# BL808 register map
Vendor: Bouffalo Lab; File version: 0.1
Registers are 32-bit, read-write, reset 0x0 unless marked. A register's access mark holds for its fields unless they carry their own. Offsets are from the block's base; [hi:lo] are bit positions; {n}, {i} and the like mark numbered series.

## TZC_NSEC — Trust zone isolation 2
Base 0x20006000
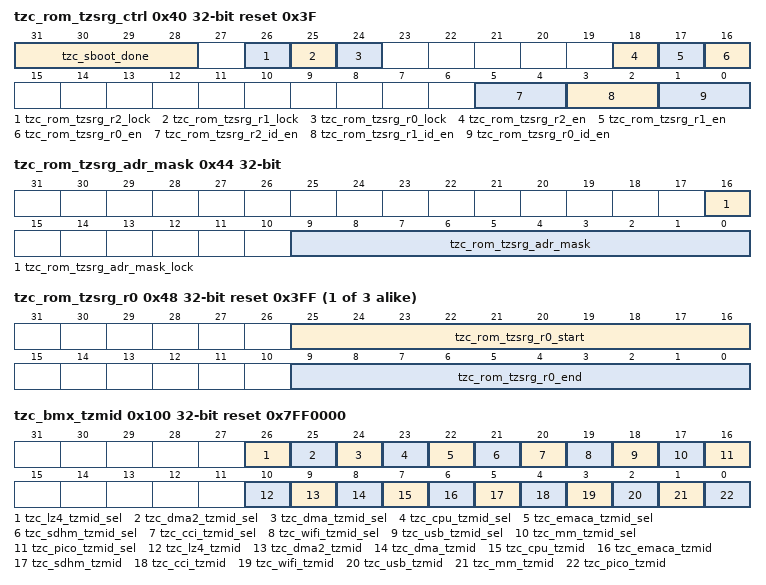
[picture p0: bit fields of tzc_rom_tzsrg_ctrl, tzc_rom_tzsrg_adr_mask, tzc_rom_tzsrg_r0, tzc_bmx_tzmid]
0x40 tzc_rom_tzsrg_ctrl reset 0x3F
  [31:28] tzc_sboot_done ro, [26] tzc_rom_tzsrg_r2_lock ro, [25] tzc_rom_tzsrg_r1_lock ro, [24] tzc_rom_tzsrg_r0_lock ro, [18] tzc_rom_tzsrg_r2_en ro, [17] tzc_rom_tzsrg_r1_en ro, [16] tzc_rom_tzsrg_r0_en ro, [5:4] tzc_rom_tzsrg_r2_id_en ro, [3:2] tzc_rom_tzsrg_r1_id_en ro, [1:0] tzc_rom_tzsrg_r0_id_en ro
0x44 tzc_rom_tzsrg_adr_mask
  [16] tzc_rom_tzsrg_adr_mask_lock ro, [9:0] tzc_rom_tzsrg_adr_mask ro
{0x48+4i} tzc_rom_tzsrg_r{i} reset 0x3FF (i=0..2)
  [25:16] tzc_rom_tzsrg_r{i}_start ro, [9:0] tzc_rom_tzsrg_r{i}_end ro
0x54 tzc_rom_tzsrg_r3
0x100 tzc_bmx_tzmid reset 0x7FF0000
  [26] tzc_lz4_tzmid_sel ro, [25] tzc_dma2_tzmid_sel ro, [24] tzc_dma_tzmid_sel ro, [23] tzc_cpu_tzmid_sel ro, [22] tzc_emaca_tzmid_sel ro, [21] tzc_sdhm_tzmid_sel ro, [20] tzc_cci_tzmid_sel ro, [19] tzc_wifi_tzmid_sel ro, [18] tzc_usb_tzmid_sel ro, [17] tzc_mm_tzmid_sel ro, [16] tzc_pico_tzmid_sel ro, [10] tzc_lz4_tzmid ro, [9] tzc_dma2_tzmid ro, [8] tzc_dma_tzmid ro, [7] tzc_cpu_tzmid ro, [6] tzc_emaca_tzmid ro, [5] tzc_sdhm_tzmid ro, [4] tzc_cci_tzmid ro, [3] tzc_wifi_tzmid ro, [2] tzc_usb_tzmid ro, [1] tzc_mm_tzmid ro, [0] tzc_pico_tzmid ro
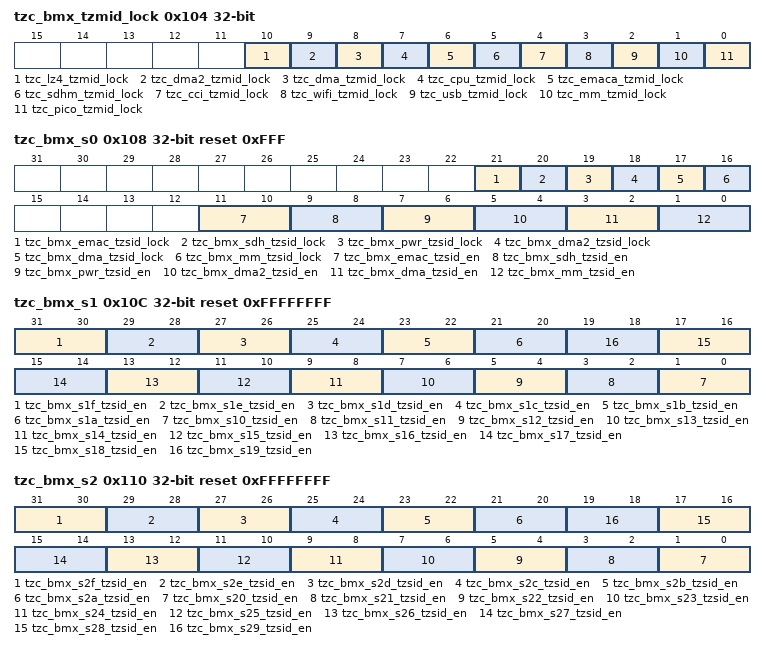
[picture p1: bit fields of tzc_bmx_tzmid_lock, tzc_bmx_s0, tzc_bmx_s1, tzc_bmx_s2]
0x104 tzc_bmx_tzmid_lock
  [10] tzc_lz4_tzmid_lock ro, [9] tzc_dma2_tzmid_lock ro, [8] tzc_dma_tzmid_lock ro, [7] tzc_cpu_tzmid_lock ro, [6] tzc_emaca_tzmid_lock ro, [5] tzc_sdhm_tzmid_lock ro, [4] tzc_cci_tzmid_lock ro, [3] tzc_wifi_tzmid_lock ro, [2] tzc_usb_tzmid_lock ro, [1] tzc_mm_tzmid_lock ro, [0] tzc_pico_tzmid_lock ro
0x108 tzc_bmx_s0 reset 0xFFF
  [21] tzc_bmx_emac_tzsid_lock ro, [20] tzc_bmx_sdh_tzsid_lock ro, [19] tzc_bmx_pwr_tzsid_lock ro, [18] tzc_bmx_dma2_tzsid_lock ro, [17] tzc_bmx_dma_tzsid_lock ro, [16] tzc_bmx_mm_tzsid_lock ro, [11:10] tzc_bmx_emac_tzsid_en ro, [9:8] tzc_bmx_sdh_tzsid_en ro, [7:6] tzc_bmx_pwr_tzsid_en ro, [5:4] tzc_bmx_dma2_tzsid_en ro, [3:2] tzc_bmx_dma_tzsid_en ro, [1:0] tzc_bmx_mm_tzsid_en ro
0x10C tzc_bmx_s1 reset 0xFFFFFFFF
  [31:30] tzc_bmx_s1f_tzsid_en ro, [29:28] tzc_bmx_s1e_tzsid_en ro, [27:26] tzc_bmx_s1d_tzsid_en ro, [25:24] tzc_bmx_s1c_tzsid_en ro, [23:22] tzc_bmx_s1b_tzsid_en ro, [21:20] tzc_bmx_s1a_tzsid_en ro, [2n-19:2n-20] tzc_bmx_s{n}_tzsid_en ro (n=10..19)
0x110 tzc_bmx_s2 reset 0xFFFFFFFF
  [31:30] tzc_bmx_s2f_tzsid_en ro, [29:28] tzc_bmx_s2e_tzsid_en ro, [27:26] tzc_bmx_s2d_tzsid_en ro, [25:24] tzc_bmx_s2c_tzsid_en ro, [23:22] tzc_bmx_s2b_tzsid_en ro, [21:20] tzc_bmx_s2a_tzsid_en ro, [2n-39:2n-40] tzc_bmx_s{n}_tzsid_en ro (n=20..29)
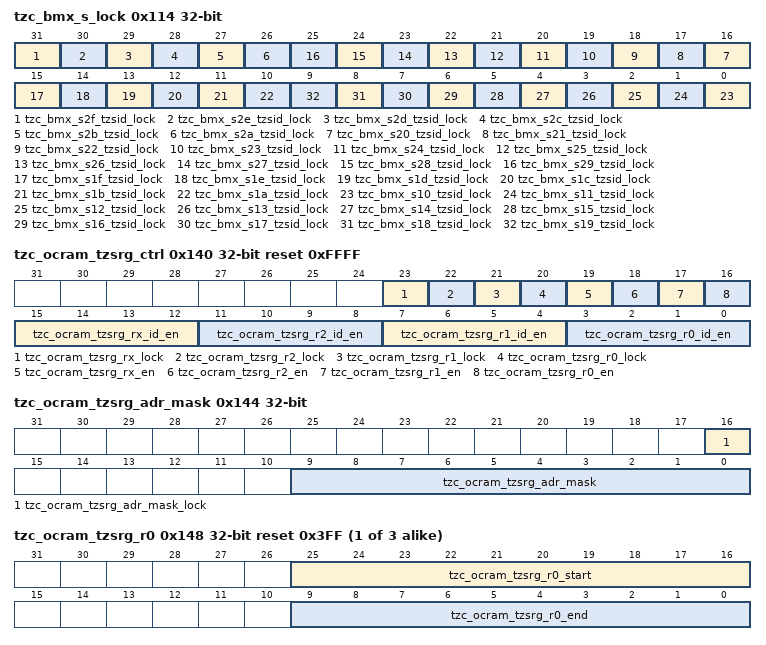
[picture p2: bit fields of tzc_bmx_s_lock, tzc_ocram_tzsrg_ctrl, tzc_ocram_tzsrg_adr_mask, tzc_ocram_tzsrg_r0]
0x114 tzc_bmx_s_lock
  [31] tzc_bmx_s2f_tzsid_lock ro, [30] tzc_bmx_s2e_tzsid_lock ro, [29] tzc_bmx_s2d_tzsid_lock ro, [28] tzc_bmx_s2c_tzsid_lock ro, [27] tzc_bmx_s2b_tzsid_lock ro, [26] tzc_bmx_s2a_tzsid_lock ro, [n-4] tzc_bmx_s{n}_tzsid_lock ro (n=20..29), [15] tzc_bmx_s1f_tzsid_lock ro, [14] tzc_bmx_s1e_tzsid_lock ro, [13] tzc_bmx_s1d_tzsid_lock ro, [12] tzc_bmx_s1c_tzsid_lock ro, [11] tzc_bmx_s1b_tzsid_lock ro, [10] tzc_bmx_s1a_tzsid_lock ro, [n-10] tzc_bmx_s{n}_tzsid_lock ro (n=10..19)
0x140 tzc_ocram_tzsrg_ctrl reset 0xFFFF
  [23] tzc_ocram_tzsrg_rx_lock ro, [22] tzc_ocram_tzsrg_r2_lock ro, [21] tzc_ocram_tzsrg_r1_lock ro, [20] tzc_ocram_tzsrg_r0_lock ro, [19] tzc_ocram_tzsrg_rx_en ro, [18] tzc_ocram_tzsrg_r2_en ro, [17] tzc_ocram_tzsrg_r1_en ro, [16] tzc_ocram_tzsrg_r0_en ro, [15:12] tzc_ocram_tzsrg_rx_id_en ro, [11:8] tzc_ocram_tzsrg_r2_id_en ro, [7:4] tzc_ocram_tzsrg_r1_id_en ro, [3:0] tzc_ocram_tzsrg_r0_id_en ro
0x144 tzc_ocram_tzsrg_adr_mask
  [16] tzc_ocram_tzsrg_adr_mask_lock ro, [9:0] tzc_ocram_tzsrg_adr_mask ro
{0x148+4i} tzc_ocram_tzsrg_r{i} reset 0x3FF (i=0..2)
  [25:16] tzc_ocram_tzsrg_r{i}_start ro, [9:0] tzc_ocram_tzsrg_r{i}_end ro
0x154 tzc_ocram_tzsrg_r3
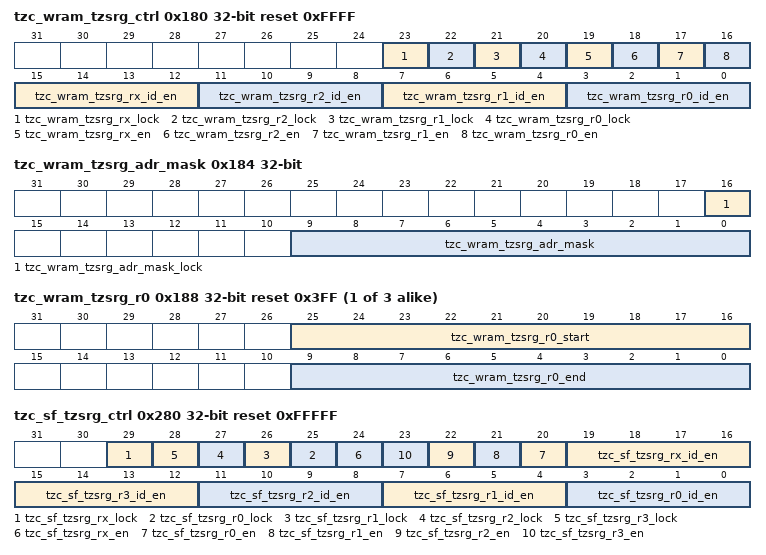
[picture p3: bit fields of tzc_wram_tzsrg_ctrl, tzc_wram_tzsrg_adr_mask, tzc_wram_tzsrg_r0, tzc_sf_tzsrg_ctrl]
0x180 tzc_wram_tzsrg_ctrl reset 0xFFFF
  [23] tzc_wram_tzsrg_rx_lock ro, [22] tzc_wram_tzsrg_r2_lock ro, [21] tzc_wram_tzsrg_r1_lock ro, [20] tzc_wram_tzsrg_r0_lock ro, [19] tzc_wram_tzsrg_rx_en ro, [18] tzc_wram_tzsrg_r2_en ro, [17] tzc_wram_tzsrg_r1_en ro, [16] tzc_wram_tzsrg_r0_en ro, [15:12] tzc_wram_tzsrg_rx_id_en ro, [11:8] tzc_wram_tzsrg_r2_id_en ro, [7:4] tzc_wram_tzsrg_r1_id_en ro, [3:0] tzc_wram_tzsrg_r0_id_en ro
0x184 tzc_wram_tzsrg_adr_mask
  [16] tzc_wram_tzsrg_adr_mask_lock ro, [9:0] tzc_wram_tzsrg_adr_mask ro
{0x188+4i} tzc_wram_tzsrg_r{i} reset 0x3FF (i=0..2)
  [25:16] tzc_wram_tzsrg_r{i}_start ro, [9:0] tzc_wram_tzsrg_r{i}_end ro
0x194 tzc_wram_tzsrg_r3
0x198 tzc_wifi_dbg reset 0x1
  [0] tzc_mac_dbg_dis ro
0x240 tzc_pdm_ctrl
0x244 tzc_uart_ctrl
0x248 tzc_i2c_ctrl
0x24C tzc_timer_ctrl
0x250 tzc_i2s_ctrl
0x280 tzc_sf_tzsrg_ctrl reset 0xFFFFF
  [29] tzc_sf_tzsrg_rx_lock ro, [n+25] tzc_sf_tzsrg_r{n}_lock ro (n=0..3), [24] tzc_sf_tzsrg_rx_en ro, [n+20] tzc_sf_tzsrg_r{n}_en ro (n=0..3), [19:16] tzc_sf_tzsrg_rx_id_en ro, [4n+3:4n] tzc_sf_tzsrg_r{n}_id_en ro (n=0..3)
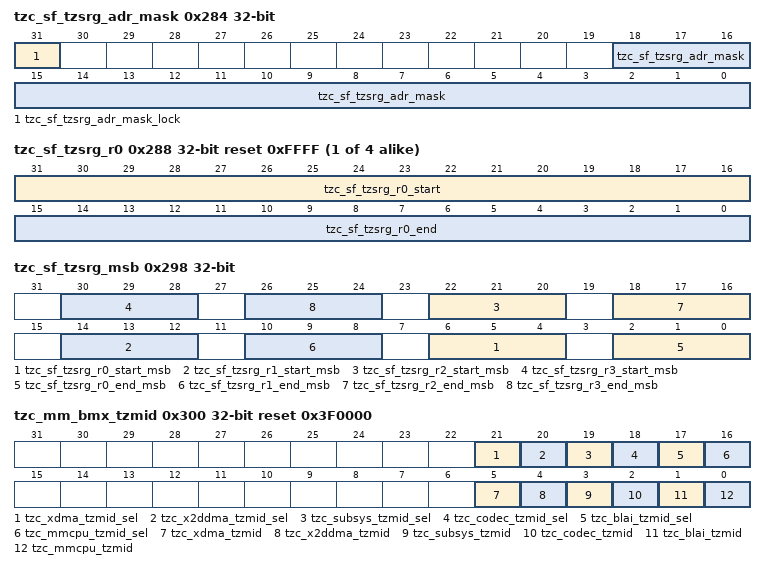
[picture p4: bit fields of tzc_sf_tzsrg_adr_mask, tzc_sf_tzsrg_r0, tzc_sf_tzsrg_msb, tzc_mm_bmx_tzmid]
0x284 tzc_sf_tzsrg_adr_mask
  [31] tzc_sf_tzsrg_adr_mask_lock ro, [18:0] tzc_sf_tzsrg_adr_mask ro
{0x288+4i} tzc_sf_tzsrg_r{i} reset 0xFFFF (i=0..3)
  [31:16] tzc_sf_tzsrg_r{i}_start ro, [15:0] tzc_sf_tzsrg_r{i}_end ro
0x298 tzc_sf_tzsrg_msb
  [8n+6:8n+4] tzc_sf_tzsrg_r{n}_start_msb ro (n=0..3), [8n+2:8n] tzc_sf_tzsrg_r{n}_end_msb ro (n=0..3)
0x300 tzc_mm_bmx_tzmid reset 0x3F0000
  [21] tzc_xdma_tzmid_sel ro, [20] tzc_x2ddma_tzmid_sel ro, [19] tzc_subsys_tzmid_sel ro, [18] tzc_codec_tzmid_sel ro, [17] tzc_blai_tzmid_sel ro, [16] tzc_mmcpu_tzmid_sel ro, [5] tzc_xdma_tzmid ro, [4] tzc_x2ddma_tzmid ro, [3] tzc_subsys_tzmid ro, [2] tzc_codec_tzmid ro, [1] tzc_blai_tzmid ro, [0] tzc_mmcpu_tzmid ro
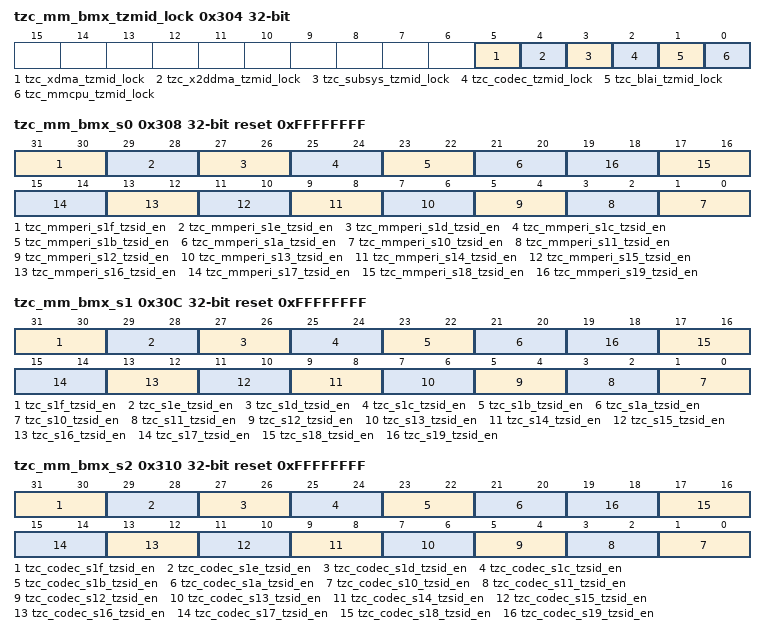
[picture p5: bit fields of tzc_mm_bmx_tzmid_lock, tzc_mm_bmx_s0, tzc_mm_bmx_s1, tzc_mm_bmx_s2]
0x304 tzc_mm_bmx_tzmid_lock
  [5] tzc_xdma_tzmid_lock ro, [4] tzc_x2ddma_tzmid_lock ro, [3] tzc_subsys_tzmid_lock ro, [2] tzc_codec_tzmid_lock ro, [1] tzc_blai_tzmid_lock ro, [0] tzc_mmcpu_tzmid_lock ro
0x308 tzc_mm_bmx_s0 reset 0xFFFFFFFF
  [31:30] tzc_mmperi_s1f_tzsid_en ro, [29:28] tzc_mmperi_s1e_tzsid_en ro, [27:26] tzc_mmperi_s1d_tzsid_en ro, [25:24] tzc_mmperi_s1c_tzsid_en ro, [23:22] tzc_mmperi_s1b_tzsid_en ro, [21:20] tzc_mmperi_s1a_tzsid_en ro, [2n-19:2n-20] tzc_mmperi_s{n}_tzsid_en ro (n=10..19)
0x30C tzc_mm_bmx_s1 reset 0xFFFFFFFF
  [31:30] tzc_s1f_tzsid_en ro, [29:28] tzc_s1e_tzsid_en ro, [27:26] tzc_s1d_tzsid_en ro, [25:24] tzc_s1c_tzsid_en ro, [23:22] tzc_s1b_tzsid_en ro, [21:20] tzc_s1a_tzsid_en ro, [2n-19:2n-20] tzc_s{n}_tzsid_en ro (n=10..19)
0x310 tzc_mm_bmx_s2 reset 0xFFFFFFFF
  [31:30] tzc_codec_s1f_tzsid_en ro, [29:28] tzc_codec_s1e_tzsid_en ro, [27:26] tzc_codec_s1d_tzsid_en ro, [25:24] tzc_codec_s1c_tzsid_en ro, [23:22] tzc_codec_s1b_tzsid_en ro, [21:20] tzc_codec_s1a_tzsid_en ro, [2n-19:2n-20] tzc_codec_s{n}_tzsid_en ro (n=10..19)
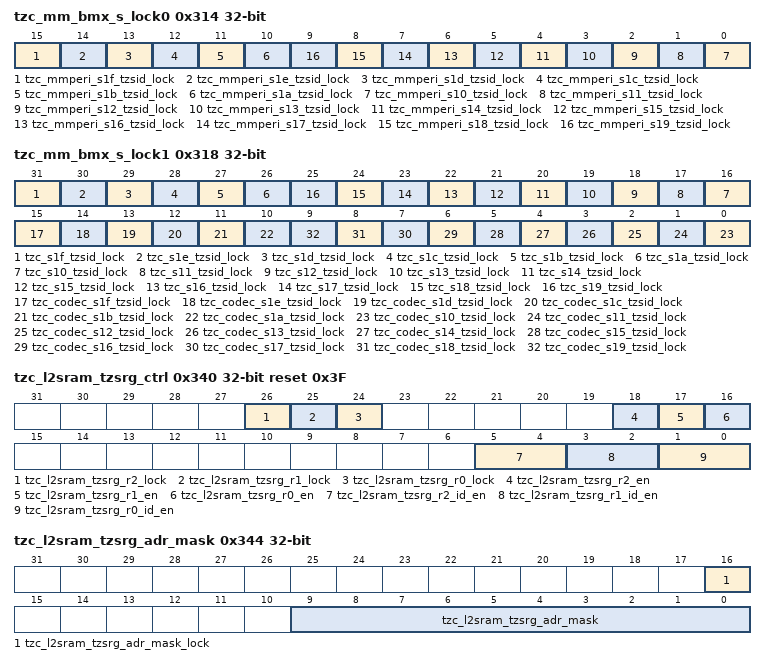
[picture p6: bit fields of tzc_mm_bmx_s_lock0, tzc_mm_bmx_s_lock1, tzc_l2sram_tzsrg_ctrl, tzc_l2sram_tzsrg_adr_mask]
0x314 tzc_mm_bmx_s_lock0
  [15] tzc_mmperi_s1f_tzsid_lock ro, [14] tzc_mmperi_s1e_tzsid_lock ro, [13] tzc_mmperi_s1d_tzsid_lock ro, [12] tzc_mmperi_s1c_tzsid_lock ro, [11] tzc_mmperi_s1b_tzsid_lock ro, [10] tzc_mmperi_s1a_tzsid_lock ro, [n-10] tzc_mmperi_s{n}_tzsid_lock ro (n=10..19)
0x318 tzc_mm_bmx_s_lock1
  [31] tzc_s1f_tzsid_lock ro, [30] tzc_s1e_tzsid_lock ro, [29] tzc_s1d_tzsid_lock ro, [28] tzc_s1c_tzsid_lock ro, [27] tzc_s1b_tzsid_lock ro, [26] tzc_s1a_tzsid_lock ro, [n+6] tzc_s{n}_tzsid_lock ro (n=10..19), [15] tzc_codec_s1f_tzsid_lock ro, [14] tzc_codec_s1e_tzsid_lock ro, [13] tzc_codec_s1d_tzsid_lock ro, [12] tzc_codec_s1c_tzsid_lock ro, [11] tzc_codec_s1b_tzsid_lock ro, [10] tzc_codec_s1a_tzsid_lock ro, [n-10] tzc_codec_s{n}_tzsid_lock ro (n=10..19)
0x340 tzc_l2sram_tzsrg_ctrl reset 0x3F
  [26] tzc_l2sram_tzsrg_r2_lock ro, [25] tzc_l2sram_tzsrg_r1_lock ro, [24] tzc_l2sram_tzsrg_r0_lock ro, [18] tzc_l2sram_tzsrg_r2_en ro, [17] tzc_l2sram_tzsrg_r1_en ro, [16] tzc_l2sram_tzsrg_r0_en ro, [5:4] tzc_l2sram_tzsrg_r2_id_en ro, [3:2] tzc_l2sram_tzsrg_r1_id_en ro, [1:0] tzc_l2sram_tzsrg_r0_id_en ro
0x344 tzc_l2sram_tzsrg_adr_mask
  [16] tzc_l2sram_tzsrg_adr_mask_lock ro, [9:0] tzc_l2sram_tzsrg_adr_mask ro
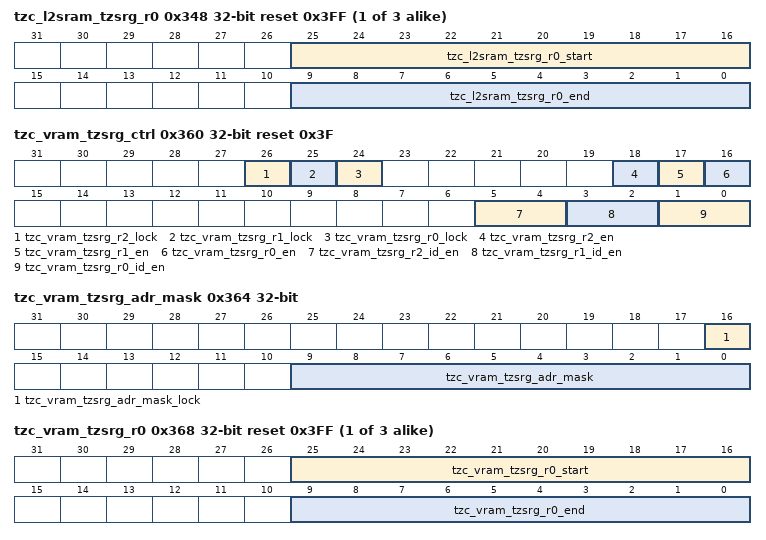
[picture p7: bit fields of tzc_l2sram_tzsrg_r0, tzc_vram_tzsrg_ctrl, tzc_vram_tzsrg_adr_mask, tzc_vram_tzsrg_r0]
{0x348+4i} tzc_l2sram_tzsrg_r{i} reset 0x3FF (i=0..2)
  [25:16] tzc_l2sram_tzsrg_r{i}_start ro, [9:0] tzc_l2sram_tzsrg_r{i}_end ro
0x354 tzc_l2sram_tzsrg_r3
0x360 tzc_vram_tzsrg_ctrl reset 0x3F
  [26] tzc_vram_tzsrg_r2_lock ro, [25] tzc_vram_tzsrg_r1_lock ro, [24] tzc_vram_tzsrg_r0_lock ro, [18] tzc_vram_tzsrg_r2_en ro, [17] tzc_vram_tzsrg_r1_en ro, [16] tzc_vram_tzsrg_r0_en ro, [5:4] tzc_vram_tzsrg_r2_id_en ro, [3:2] tzc_vram_tzsrg_r1_id_en ro, [1:0] tzc_vram_tzsrg_r0_id_en ro
0x364 tzc_vram_tzsrg_adr_mask
  [16] tzc_vram_tzsrg_adr_mask_lock ro, [9:0] tzc_vram_tzsrg_adr_mask ro
{0x368+4i} tzc_vram_tzsrg_r{i} reset 0x3FF (i=0..2)
  [25:16] tzc_vram_tzsrg_r{i}_start ro, [9:0] tzc_vram_tzsrg_r{i}_end ro
0x374 tzc_vram_tzsrg_r3
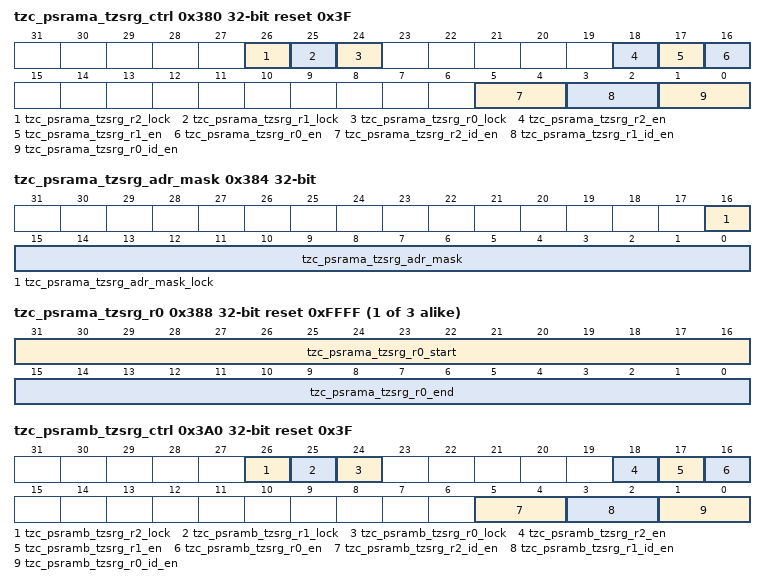
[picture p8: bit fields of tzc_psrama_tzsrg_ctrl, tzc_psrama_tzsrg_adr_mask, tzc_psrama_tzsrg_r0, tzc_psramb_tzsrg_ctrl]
0x380 tzc_psrama_tzsrg_ctrl reset 0x3F
  [26] tzc_psrama_tzsrg_r2_lock ro, [25] tzc_psrama_tzsrg_r1_lock ro, [24] tzc_psrama_tzsrg_r0_lock ro, [18] tzc_psrama_tzsrg_r2_en ro, [17] tzc_psrama_tzsrg_r1_en ro, [16] tzc_psrama_tzsrg_r0_en ro, [5:4] tzc_psrama_tzsrg_r2_id_en ro, [3:2] tzc_psrama_tzsrg_r1_id_en ro, [1:0] tzc_psrama_tzsrg_r0_id_en ro
0x384 tzc_psrama_tzsrg_adr_mask
  [16] tzc_psrama_tzsrg_adr_mask_lock ro, [15:0] tzc_psrama_tzsrg_adr_mask ro
{0x388+4i} tzc_psrama_tzsrg_r{i} reset 0xFFFF (i=0..2)
  [31:16] tzc_psrama_tzsrg_r{i}_start ro, [15:0] tzc_psrama_tzsrg_r{i}_end ro
0x394 tzc_psrama_tzsrg_r3
0x3A0 tzc_psramb_tzsrg_ctrl reset 0x3F
  [26] tzc_psramb_tzsrg_r2_lock ro, [25] tzc_psramb_tzsrg_r1_lock ro, [24] tzc_psramb_tzsrg_r0_lock ro, [18] tzc_psramb_tzsrg_r2_en ro, [17] tzc_psramb_tzsrg_r1_en ro, [16] tzc_psramb_tzsrg_r0_en ro, [5:4] tzc_psramb_tzsrg_r2_id_en ro, [3:2] tzc_psramb_tzsrg_r1_id_en ro, [1:0] tzc_psramb_tzsrg_r0_id_en ro
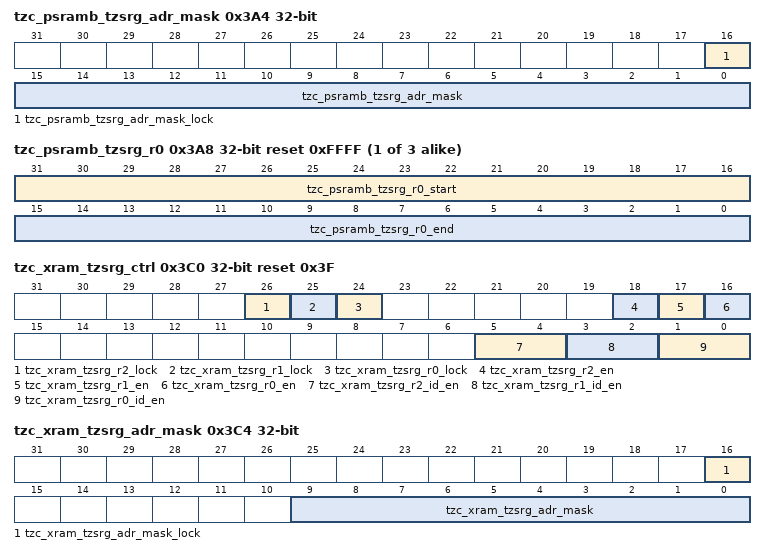
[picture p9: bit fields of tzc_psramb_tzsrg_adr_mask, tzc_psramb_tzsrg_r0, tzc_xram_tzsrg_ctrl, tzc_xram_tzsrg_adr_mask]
0x3A4 tzc_psramb_tzsrg_adr_mask
  [16] tzc_psramb_tzsrg_adr_mask_lock ro, [15:0] tzc_psramb_tzsrg_adr_mask ro
{0x3A8+4i} tzc_psramb_tzsrg_r{i} reset 0xFFFF (i=0..2)
  [31:16] tzc_psramb_tzsrg_r{i}_start ro, [15:0] tzc_psramb_tzsrg_r{i}_end ro
0x3B4 tzc_psramb_tzsrg_r3
0x3C0 tzc_xram_tzsrg_ctrl reset 0x3F
  [26] tzc_xram_tzsrg_r2_lock ro, [25] tzc_xram_tzsrg_r1_lock ro, [24] tzc_xram_tzsrg_r0_lock ro, [18] tzc_xram_tzsrg_r2_en ro, [17] tzc_xram_tzsrg_r1_en ro, [16] tzc_xram_tzsrg_r0_en ro, [5:4] tzc_xram_tzsrg_r2_id_en ro, [3:2] tzc_xram_tzsrg_r1_id_en ro, [1:0] tzc_xram_tzsrg_r0_id_en ro
0x3C4 tzc_xram_tzsrg_adr_mask
  [16] tzc_xram_tzsrg_adr_mask_lock ro, [9:0] tzc_xram_tzsrg_adr_mask ro
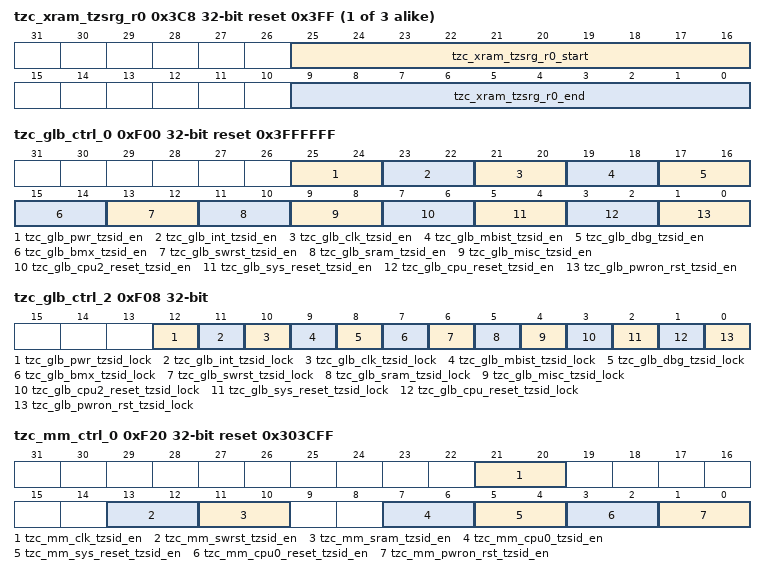
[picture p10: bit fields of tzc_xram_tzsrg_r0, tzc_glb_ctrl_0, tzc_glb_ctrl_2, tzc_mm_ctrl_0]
{0x3C8+4i} tzc_xram_tzsrg_r{i} reset 0x3FF (i=0..2)
  [25:16] tzc_xram_tzsrg_r{i}_start ro, [9:0] tzc_xram_tzsrg_r{i}_end ro
0x3D4 tzc_xram_tzsrg_r3
0xF00 tzc_glb_ctrl_0 reset 0x3FFFFFF
  [25:24] tzc_glb_pwr_tzsid_en ro, [23:22] tzc_glb_int_tzsid_en ro, [21:20] tzc_glb_clk_tzsid_en ro, [19:18] tzc_glb_mbist_tzsid_en ro, [17:16] tzc_glb_dbg_tzsid_en ro, [15:14] tzc_glb_bmx_tzsid_en ro, [13:12] tzc_glb_swrst_tzsid_en ro, [11:10] tzc_glb_sram_tzsid_en ro, [9:8] tzc_glb_misc_tzsid_en ro, [7:6] tzc_glb_cpu2_reset_tzsid_en ro, [5:4] tzc_glb_sys_reset_tzsid_en ro, [3:2] tzc_glb_cpu_reset_tzsid_en ro, [1:0] tzc_glb_pwron_rst_tzsid_en ro
0xF04 tzc_glb_ctrl_1
0xF08 tzc_glb_ctrl_2
  [12] tzc_glb_pwr_tzsid_lock ro, [11] tzc_glb_int_tzsid_lock ro, [10] tzc_glb_clk_tzsid_lock ro, [9] tzc_glb_mbist_tzsid_lock ro, [8] tzc_glb_dbg_tzsid_lock ro, [7] tzc_glb_bmx_tzsid_lock ro, [6] tzc_glb_swrst_tzsid_lock ro, [5] tzc_glb_sram_tzsid_lock ro, [4] tzc_glb_misc_tzsid_lock ro, [3] tzc_glb_cpu2_reset_tzsid_lock ro, [2] tzc_glb_sys_reset_tzsid_lock ro, [1] tzc_glb_cpu_reset_tzsid_lock ro, [0] tzc_glb_pwron_rst_tzsid_lock ro
0xF20 tzc_mm_ctrl_0 reset 0x303CFF
  [21:20] tzc_mm_clk_tzsid_en ro, [13:12] tzc_mm_swrst_tzsid_en ro, [11:10] tzc_mm_sram_tzsid_en ro, [7:6] tzc_mm_cpu0_tzsid_en ro, [5:4] tzc_mm_sys_reset_tzsid_en ro, [3:2] tzc_mm_cpu0_reset_tzsid_en ro, [1:0] tzc_mm_pwron_rst_tzsid_en ro
0xF24 tzc_mm_ctrl_1
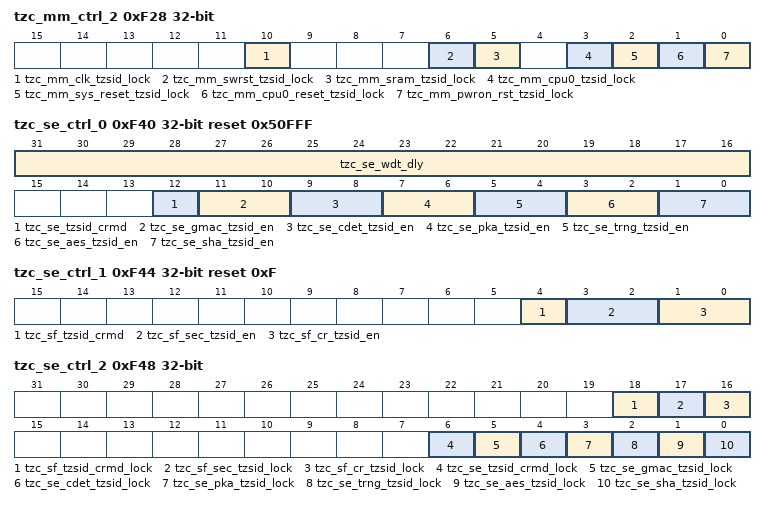
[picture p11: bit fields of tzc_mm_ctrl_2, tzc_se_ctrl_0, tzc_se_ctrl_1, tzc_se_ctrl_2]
0xF28 tzc_mm_ctrl_2
  [10] tzc_mm_clk_tzsid_lock ro, [6] tzc_mm_swrst_tzsid_lock ro, [5] tzc_mm_sram_tzsid_lock ro, [3] tzc_mm_cpu0_tzsid_lock ro, [2] tzc_mm_sys_reset_tzsid_lock ro, [1] tzc_mm_cpu0_reset_tzsid_lock ro, [0] tzc_mm_pwron_rst_tzsid_lock ro
0xF40 tzc_se_ctrl_0 reset 0x50FFF
  [31:16] tzc_se_wdt_dly ro, [12] tzc_se_tzsid_crmd ro, [11:10] tzc_se_gmac_tzsid_en ro, [9:8] tzc_se_cdet_tzsid_en ro, [7:6] tzc_se_pka_tzsid_en ro, [5:4] tzc_se_trng_tzsid_en ro, [3:2] tzc_se_aes_tzsid_en ro, [1:0] tzc_se_sha_tzsid_en ro
0xF44 tzc_se_ctrl_1 reset 0xF
  [4] tzc_sf_tzsid_crmd ro, [3:2] tzc_sf_sec_tzsid_en ro, [1:0] tzc_sf_cr_tzsid_en ro
0xF48 tzc_se_ctrl_2
  [18] tzc_sf_tzsid_crmd_lock ro, [17] tzc_sf_sec_tzsid_lock ro, [16] tzc_sf_cr_tzsid_lock ro, [6] tzc_se_tzsid_crmd_lock ro, [5] tzc_se_gmac_tzsid_lock ro, [4] tzc_se_cdet_tzsid_lock ro, [3] tzc_se_pka_tzsid_lock ro, [2] tzc_se_trng_tzsid_lock ro, [1] tzc_se_aes_tzsid_lock ro, [0] tzc_se_sha_tzsid_lock ro
